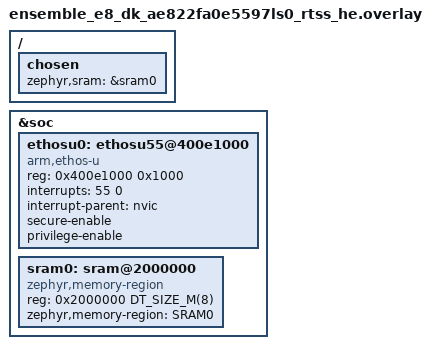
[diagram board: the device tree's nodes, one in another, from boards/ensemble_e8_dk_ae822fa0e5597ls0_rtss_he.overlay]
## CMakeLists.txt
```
# Copyright (c) Meta Platforms, Inc. and affiliates.
# All rights reserved.
# Copyright 2025-2026 Arm Limited and/or its affiliates.
#
# SPDX-License-Identifier: Apache-2.0

cmake_minimum_required(VERSION 3.24)

set(CMAKE_SKIP_INSTALL_RULES
    ON
    CACHE BOOL "" FORCE
)

set(ET_PTE_FILE_PATH
    ""
    CACHE FILEPATH "Path to the ExecuTorch .pte (or .bpte) model to embed"
)
set(ET_PTE_SECTION
    "network_model_sec"
    CACHE STRING "Section attribute used for the generated model data"
)

if(NOT ET_PTE_FILE_PATH)
  message(
    FATAL_ERROR
      "ET_PTE_FILE_PATH must point to the ExecuTorch .pte (or .bpte) model to embed."
  )
endif()

if(NOT IS_ABSOLUTE "${ET_PTE_FILE_PATH}")
  get_filename_component(
    ET_PTE_FILE_PATH "${ET_PTE_FILE_PATH}" ABSOLUTE BASE_DIR
    "${CMAKE_CURRENT_SOURCE_DIR}"
  )
endif()

if(NOT EXISTS "${ET_PTE_FILE_PATH}")
  message(
    FATAL_ERROR
      "Could not find ExecuTorch model at ET_PTE_FILE_PATH: ${ET_PTE_FILE_PATH}"
  )
endif()

set(ET_PTE_FILE_PATH
    "${ET_PTE_FILE_PATH}"
    CACHE FILEPATH "Path to the ExecuTorch .pte (or .bpte) model to embed"
          FORCE
)

find_package(
  Python3
  COMPONENTS Interpreter
  REQUIRED
)

execute_process(
  COMMAND
    ${Python3_EXECUTABLE}
    "${CMAKE_CURRENT_LIST_DIR}/../../../codegen/tools/gen_oplist.py"
    --model_file_path=${ET_PTE_FILE_PATH}
    --output_path=${CMAKE_CURRENT_BINARY_DIR}/temp.yaml
  RESULT_VARIABLE GEN_OPLIST_RESULT
  OUTPUT_VARIABLE CMD_RESULT
  ERROR_VARIABLE GEN_OPLIST_ERROR
)

if(NOT GEN_OPLIST_RESULT EQUAL 0)
  message(
    FATAL_ERROR
      "gen_oplist.py failed with exit code ${GEN_OPLIST_RESULT}: ${GEN_OPLIST_ERROR}"
  )
endif()

if(CMD_RESULT MATCHES "aten::" OR CMD_RESULT MATCHES "dim_order_ops::")
  set(FOUND_OPS_IN_FILE "true")
else()
  set(FOUND_OPS_IN_FILE "false")
endif()

if(${FOUND_OPS_IN_FILE})
  set(EXECUTORCH_SELECT_OPS_LIST "")
  set(EXECUTORCH_SELECT_OPS_MODEL
      "${ET_PTE_FILE_PATH}"
      CACHE STRING "Select operators from this ExecuTorch model" FORCE
  )
  set(_EXECUTORCH_GEN_ZEPHYR_PORTABLE_OPS ON)
  message(
    "gen_oplist:  EXECUTORCH_SELECT_OPS_MODEL=${ET_PTE_FILE_PATH} is used to auto generate ops from"
  )
else()
  set(EXECUTORCH_SELECT_OPS_LIST "")
  set(EXECUTORCH_SELECT_OPS_MODEL "")
  set(_EXECUTORCH_GEN_ZEPHYR_PORTABLE_OPS OFF)
  message(
    "gen_oplist: No aten:: or dim_order_ops:: operators were found in ${ET_PTE_FILE_PATH}; skipping portable operator selection. Other CPU operators may still run."
  )
endif()

find_package(Zephyr REQUIRED HINTS $ENV{ZEPHYR_BASE})

dt_nodelabel(model_ddr_path NODELABEL "model_ddr")
if(model_ddr_path)
  configure_file(
    model_section.ld.in ${CMAKE_CURRENT_BINARY_DIR}/model_section.ld @ONLY
  )
  zephyr_linker_sources(SECTIONS ${CMAKE_CURRENT_BINARY_DIR}/model_section.ld)
endif()

project(executorch_mv2_ethosu)

set(CMAKE_CXX_FLAGS
    "${CMAKE_CXX_FLAGS} -Wall -Wno-switch -Wno-float-conversion -ffunction-sections -fdata-sections"
)

if(NOT DEFINED EXECUTORCH_DIR)
  message(
    STATUS
      "ZEPHYR_EXECUTORCH_MODULE_DIR set to : ${ZEPHYR_EXECUTORCH_MODULE_DIR}"
  )
  if(DEFINED ZEPHYR_EXECUTORCH_MODULE_DIR)
    set(EXECUTORCH_DIR ${ZEPHYR_EXECUTORCH_MODULE_DIR})
    message(
      STATUS "Using Zephyr module discovery: EXECUTORCH_DIR=${EXECUTORCH_DIR}"
    )
  else()
    message(
      FATAL_ERROR
        "ExecuTorch module not found. Ensure it's properly configured in your Zephyr workspace."
    )
  endif()
else()
  message(STATUS "Using predefined EXECUTORCH_DIR=${EXECUTORCH_DIR}")
endif()

set(EXECUTORCH_ROOT ${EXECUTORCH_DIR})
include(${EXECUTORCH_DIR}/tools/cmake/Utils.cmake)

if(NOT TARGET portable_kernels)
  set(EXECUTORCH_PORTABLE_BUILD_KERNELS_ONLY ON)
  add_subdirectory(
    ${EXECUTORCH_DIR}/kernels/portable
    ${CMAKE_CURRENT_BINARY_DIR}/executorch/kernels/portable
  )
  unset(EXECUTORCH_PORTABLE_BUILD_KERNELS_ONLY)
endif()
set(EXECUTORCH_OPS_LIB "")
if(_EXECUTORCH_GEN_ZEPHYR_PORTABLE_OPS)
  include(${EXECUTORCH_DIR}/tools/cmake/Codegen.cmake)
  if(NOT DEFINED EXECUTORCH_ENABLE_DTYPE_SELECTIVE_BUILD)
    set(EXECUTORCH_ENABLE_DTYPE_SELECTIVE_BUILD "")
  endif()
  gen_selected_ops(
    LIB_NAME
    "cpu_portable_ops_lib"
    OPS_SCHEMA_YAML
    ""
    SELECT_OPS_LIST
    "${EXECUTORCH_SELECT_OPS_LIST}"
    INCLUDE_ALL_OPS
    ""
    OPS_FROM_MODEL
    "${EXECUTORCH_SELECT_OPS_MODEL}"
    DTYPE_SELECTIVE_BUILD
    "${EXECUTORCH_ENABLE_DTYPE_SELECTIVE_BUILD}"
  )
  generate_bindings_for_kernels(
    LIB_NAME "cpu_portable_ops_lib" FUNCTIONS_YAML
    ${EXECUTORCH_DIR}/kernels/portable/functions.yaml DTYPE_SELECTIVE_BUILD
    "${EXECUTORCH_ENABLE_DTYPE_SELECTIVE_BUILD}"
  )
  gen_operators_lib(
    LIB_NAME
    "cpu_portable_ops_lib"
    KERNEL_LIBS
    portable_kernels
    DEPS
    executorch
    DTYPE_SELECTIVE_BUILD
    "${EXECUTORCH_ENABLE_DTYPE_SELECTIVE_BUILD}"
  )
  set(EXECUTORCH_OPS_LIB "cpu_portable_ops_lib")
endif()

set(_local_flatcc_root ${CMAKE_BINARY_DIR}/flatcc_src)
if(NOT EXISTS ${_local_flatcc_root}/CMakeLists.txt)
  file(MAKE_DIRECTORY ${_local_flatcc_root})
  execute_process(
    COMMAND ${CMAKE_COMMAND} -E copy_directory
            ${EXECUTORCH_DIR}/third-party/flatcc ${_local_flatcc_root}
  )
endif()
set(EXECUTORCH_FLATCC_SOURCE_ROOT
    ${_local_flatcc_root}
    CACHE PATH "" FORCE
)
set(EXECUTORCH_FLATCC_INSTALL_ROOT
    ${_local_flatcc_root}
    CACHE PATH "" FORCE
)

set(app_sources src/main.cpp
                ${EXECUTORCH_DIR}/examples/arm/common/arm_memory_allocator.cpp
)
target_sources(app PRIVATE ${app_sources})

set(_model_pte_header ${CMAKE_CURRENT_BINARY_DIR}/model_pte.h)
add_custom_command(
  OUTPUT ${_model_pte_header}
  COMMAND
    ${Python3_EXECUTABLE} ${EXECUTORCH_DIR}/examples/arm/common/pte_to_header.py
    --pte ${ET_PTE_FILE_PATH} --outdir ${CMAKE_CURRENT_BINARY_DIR} --section
    ${ET_PTE_SECTION}
  DEPENDS ${ET_PTE_FILE_PATH}
          ${EXECUTORCH_DIR}/examples/arm/common/pte_to_header.py
  COMMENT "Converting ${ET_PTE_FILE_PATH} to model_pte.h"
)
add_custom_target(gen_model_header DEPENDS ${_model_pte_header})
add_dependencies(app gen_model_header)

if(DEFINED CONFIG_EXECUTORCH_METHOD_ALLOCATOR_POOL_SIZE)
  target_compile_definitions(
    app
    PRIVATE
      ET_ARM_METHOD_ALLOCATOR_POOL_SIZE=${CONFIG_EXECUTORCH_METHOD_ALLOCATOR_POOL_SIZE}
  )
endif()
if(DEFINED CONFIG_EXECUTORCH_TEMP_ALLOCATOR_POOL_SIZE)
  target_compile_definitions(
    app
    PRIVATE
      ET_ARM_BAREMETAL_SCRATCH_TEMP_ALLOCATOR_POOL_SIZE=${CONFIG_EXECUTORCH_TEMP_ALLOCATOR_POOL_SIZE}
  )
endif()
if(CONFIG_ET_ARM_MODEL_PTE_DMA_ACCESSIBLE)
  target_compile_definitions(app PRIVATE ET_ARM_MODEL_PTE_DMA_ACCESSIBLE)
endif()

target_link_libraries(app PRIVATE libexecutorch)
if(EXECUTORCH_OPS_LIB)
  target_link_libraries(app PRIVATE ${EXECUTORCH_OPS_LIB})
endif()
if(CONFIG_CPU_CORTEX_M)
  if(TARGET cortex_m_ops_lib)
    target_link_libraries(app PRIVATE cortex_m_ops_lib)
  endif()
  if(TARGET cortex_m_kernels)
    executorch_target_link_options_shared_lib(cortex_m_kernels)
    target_link_libraries(app PRIVATE cortex_m_kernels)
  endif()
endif()
if(TARGET quantized_kernels)
  executorch_target_link_options_shared_lib(quantized_kernels)
  target_link_libraries(app PRIVATE quantized_kernels)
endif()
if(TARGET portable_kernels)
  executorch_target_link_options_shared_lib(portable_kernels)
  target_link_libraries(app PRIVATE portable_kernels)
endif()
if(TARGET executorch_delegate_ethos_u)
  executorch_target_link_options_shared_lib(executorch_delegate_ethos_u)
  target_link_libraries(app PRIVATE executorch_delegate_ethos_u)
endif()
if(TARGET ethosu_core_driver)
  target_link_libraries(app PRIVATE ethosu_core_driver)
endif()

target_include_directories(app PRIVATE src ${CMAKE_CURRENT_BINARY_DIR})
get_target_property(OUT app LINK_LIBRARIES)
message(STATUS ${OUT})
```

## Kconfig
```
# Copyright (c) Meta Platforms, Inc. and affiliates.
# All rights reserved.
# Copyright 2025-2026 Arm Limited and/or its affiliates.
#
# SPDX-License-Identifier: Apache-2.0

source "Kconfig.zephyr"

menu "ExecuTorch MobileNetV2 sample configuration"

config ET_ARM_MODEL_PTE_DMA_ACCESSIBLE
	bool "Model PTE is in DMA-accessible memory"
	default n
	help
	  Skip copying the model PTE blob to a separate SRAM buffer at
	  runtime. Enable this when the embedded model blob already resides
	  in memory the Ethos-U NPU can DMA from (e.g. DDR on Corstone FVP,
	  MRAM on Alif). This is independent of where the linker places the
	  model section; DDR placement is controlled by the model_ddr DTS
	  node in the board overlay.

config EXECUTORCH_METHOD_ALLOCATOR_POOL_SIZE
	int "Method allocator pool size in bytes"
	default 1572864
	depends on EXECUTORCH
	help
	  Size of the method allocator pool in bytes. MobileNetV2 requires
	  more memory than simple models. Default is 1.5MB which is sufficient
	  for a fully NPU-delegated INT8 MobileNetV2 model.

config EXECUTORCH_TEMP_ALLOCATOR_POOL_SIZE
	int "Temporary allocator pool size in bytes"
	default 1572864
	depends on EXECUTORCH
	help
	  Size of the temporary allocator pool in bytes. Default is 1.5MB
	  which provides sufficient scratch space for MobileNetV2 inference
	  on Ethos-U NPU.

endmenu
```

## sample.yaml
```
sample:
  name: ExecuTorch MobileNetV2 Ethos-U
  description: MobileNetV2 image classification using ExecuTorch with Ethos-U NPU
common:
  tags:
    - executorch
    - ml
    - npu
    - ethos-u
    - mv2
    - image-classification
  depends_on:
    - executorch
    - arm_ethos_u
```

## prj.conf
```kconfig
# Copyright (c) Meta Platforms, Inc. and affiliates.
# All rights reserved.
# Copyright 2025-2026 Arm Limited and/or its affiliates.
#
# SPDX-License-Identifier: Apache-2.0

# Enable ExecuTorch
CONFIG_EXECUTORCH=y

# C++
CONFIG_CPP=y
CONFIG_STD_CPP17=y

# Config - increased for MobileNetV2 memory requirements
CONFIG_MAIN_STACK_SIZE=16384
CONFIG_HEAP_MEM_POOL_SIZE=65536

# Logging
CONFIG_REQUIRES_FLOAT_PRINTF=y

# Configuration for selective operator builds
CONFIG_EXECUTORCH_BUILD_PORTABLE_OPS=n

# Enable Helium (MVE) builds of CMSIS-NN by selecting the FPU and hard-float ABI.
CONFIG_FPU=y
CONFIG_FP_HARDABI=y

# Setup memory requirements for MobileNetV2.
# MV2 is a larger model than the default hello-executorch add model.
CONFIG_EXECUTORCH_METHOD_ALLOCATOR_POOL_SIZE=1572864
CONFIG_EXECUTORCH_TEMP_ALLOCATOR_POOL_SIZE=1572864
```

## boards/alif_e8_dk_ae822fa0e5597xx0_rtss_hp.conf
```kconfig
# Copyright (c) Meta Platforms, Inc. and affiliates.
#
# Copyright 2026 Arm Limited and/or its affiliates.
#
# SPDX-License-Identifier: Apache-2.0
#
# Alif Ensemble E8 DevKit (HP core): Ethos-U55 with 256 MACs.
# MRAM is DMA-accessible by the NPU so no SRAM copy is needed.
CONFIG_ETHOS_U=y
CONFIG_ET_ARM_MODEL_PTE_DMA_ACCESSIBLE=y
```

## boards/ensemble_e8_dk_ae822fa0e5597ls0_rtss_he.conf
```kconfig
# Copyright (c) Meta Platforms, Inc. and affiliates.
#
# Copyright 2026 Arm Limited and/or its affiliates.
#
# SPDX-License-Identifier: Apache-2.0

# Keep the linked image address in sync with the Alif ATOC mramAddress used by
# this sample's generated zephyr.json.
CONFIG_FLASH_LOAD_OFFSET=0x8000

# Enable the Zephyr Ethos-U driver so the ExecuTorch Arm backend is built and
# the EthosUBackend delegate is registered at runtime.
CONFIG_ETHOS_U=y
CONFIG_ETHOS_U55_128=y

# Alif MRAM is DMA-accessible by the NPU, so avoid duplicating the model into
# SRAM at startup.
CONFIG_ET_ARM_MODEL_PTE_DMA_ACCESSIBLE=y
```

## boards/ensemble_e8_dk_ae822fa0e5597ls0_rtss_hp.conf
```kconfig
# Copyright (c) Meta Platforms, Inc. and affiliates.
#
# Copyright 2026 Arm Limited and/or its affiliates.
#
# SPDX-License-Identifier: Apache-2.0

# Keep the linked image address in sync with the Alif ATOC mramAddress used by
# this sample's generated zephyr.json.
CONFIG_FLASH_LOAD_OFFSET=0x8000

# Enable the Zephyr Ethos-U driver so the ExecuTorch Arm backend is built and
# the EthosUBackend delegate is registered at runtime.
CONFIG_ETHOS_U=y
CONFIG_ETHOS_U55_256=y

# Alif MRAM is DMA-accessible by the NPU, so avoid duplicating the model into
# SRAM at startup.
CONFIG_ET_ARM_MODEL_PTE_DMA_ACCESSIBLE=y
```

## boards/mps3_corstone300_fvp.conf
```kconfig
# Copyright (c) Meta Platforms, Inc. and affiliates.
#
# Copyright 2026 Arm Limited and/or its affiliates.
#
# SPDX-License-Identifier: Apache-2.0
#
# Enable the Zephyr Ethos-U driver so executorch_delegate_ethos_u can reserve
# and use the hardware instance exposed by the board DTS.
CONFIG_ETHOS_U=y

# Model PTE is placed in DDR via linker snippet; the Ethos-U can DMA from
# DDR on the FVP so no SRAM copy is needed.
CONFIG_ET_ARM_MODEL_PTE_DMA_ACCESSIBLE=y

# Corstone-300 has 2 MiB ISRAM.  With the model in DDR the method pool
# needs ~1.4 MiB (752 KiB planned buffer + 602 KiB input tensor).
# The remaining ISRAM is not enough for the Ethos-U scratch (~1.5 MiB),
# so MV2 inference will fail at runtime on this board; Corstone-320 is
# the supported target for MV2.  These sizes keep the link step green.
CONFIG_EXECUTORCH_METHOD_ALLOCATOR_POOL_SIZE=786432
CONFIG_EXECUTORCH_TEMP_ALLOCATOR_POOL_SIZE=786432
```

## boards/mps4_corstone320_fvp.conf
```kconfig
# Copyright (c) Meta Platforms, Inc. and affiliates.
#
# Copyright 2026 Arm Limited and/or its affiliates.
#
# SPDX-License-Identifier: Apache-2.0
#
# Enable the Zephyr Ethos-U driver so executorch_delegate_ethos_u can reserve
# and use the hardware instance exposed by the board DTS.
CONFIG_ETHOS_U=y

# Model PTE is placed in DDR via linker snippet; the Ethos-U can DMA from
# DDR on the FVP so no SRAM copy is needed.
CONFIG_ET_ARM_MODEL_PTE_DMA_ACCESSIBLE=y

# The overlay reserves 3.5 MiB of ISRAM for writable data, including these pools.
CONFIG_EXECUTORCH_METHOD_ALLOCATOR_POOL_SIZE=1572864
CONFIG_EXECUTORCH_TEMP_ALLOCATOR_POOL_SIZE=1572864
```

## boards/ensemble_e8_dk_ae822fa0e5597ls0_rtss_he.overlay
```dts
/* Copyright (c) Meta Platforms, Inc. and affiliates.
 *
 * Copyright 2026 Arm Limited and/or its affiliates.
 *
 * SPDX-License-Identifier: Apache-2.0
 */

/* The default board DTS routes Zephyr RAM to 256 KiB DTCM on RTSS-HE.
 * MobileNetV2 needs much more space, so expose the contiguous SRAM0 and SRAM1
 * banks as one 8 MiB Zephyr RAM region for this sample.
 */

/delete-node/ &sram0;
/delete-node/ &sram1;

&soc {
	ethosu0: ethosu55@400e1000 {
		compatible = "arm,ethos-u";
		reg = <0x400e1000 0x1000>;
		interrupts = <55 0>;
		interrupt-parent = <&nvic>;
		secure-enable;
		privilege-enable;
		status = "okay";
	};

	sram0: sram@2000000 {
		compatible = "zephyr,memory-region", "mmio-sram";
		reg = <0x2000000 DT_SIZE_M(8)>;
		zephyr,memory-region = "SRAM0";
	};
};

/ {
	chosen {
		zephyr,sram = &sram0;
	};
};
```

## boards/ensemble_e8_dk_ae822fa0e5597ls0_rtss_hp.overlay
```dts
/* Copyright (c) Meta Platforms, Inc. and affiliates.
 *
 * Copyright 2026 Arm Limited and/or its affiliates.
 *
 * SPDX-License-Identifier: Apache-2.0
 */

/* The default board DTS routes Zephyr RAM to 1 MiB DTCM. MobileNetV2 allocator
 * pools exceed that space, so expose the contiguous SRAM0 and SRAM1 banks as
 * one 8 MiB Zephyr RAM region for this sample.
 */

/delete-node/ &sram0;
/delete-node/ &sram1;

&soc {
	ethosu0: ethosu55@400e1000 {
		compatible = "arm,ethos-u";
		reg = <0x400e1000 0x1000>;
		interrupts = <55 0>;
		interrupt-parent = <&nvic>;
		secure-enable;
		privilege-enable;
		status = "okay";
	};

	sram0: sram@2000000 {
		compatible = "zephyr,memory-region", "mmio-sram";
		reg = <0x2000000 DT_SIZE_M(8)>;
		zephyr,memory-region = "SRAM0";
	};
};

/ {
	chosen {
		zephyr,sram = &sram0;
	};
};
```

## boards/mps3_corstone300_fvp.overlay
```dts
/* Copyright (c) Meta Platforms, Inc. and affiliates.
 *
 * Copyright 2026 Arm Limited and/or its affiliates.
 *
 * SPDX-License-Identifier: Apache-2.0
 */

/* Ensure ExecuTorch scratch buffers live in shared SRAM that the Ethos-U
 * DMA can access. The default board DTS routes Zephyr's general-purpose
 * SRAM to DTCM, which the NPU cannot reach. Override the choice so that
 * .data/.bss land in ISRAM (0x3100_0000) instead.
 *
 * The model PTE blob is placed in DDR (0x7000_0000) via a linker snippet
 * to avoid overflowing the 2 MiB ISRAM and 512 KiB ITCM regions.
 * The Ethos-U can DMA from DDR on the Corstone-300 FVP.
 */
/ {
	chosen {
		zephyr,sram = &isram;
	};

	model_ddr: memory@70000000 {
		compatible = "zephyr,memory-region", "mmio-sram";
		reg = <0x70000000 DT_SIZE_M(16)>;
		zephyr,memory-region = "MODEL_DDR";
	};
};
```

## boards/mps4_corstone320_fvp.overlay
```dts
/* Copyright (c) Meta Platforms, Inc. and affiliates.
 *
 * Copyright 2026 Arm Limited and/or its affiliates.
 *
 * SPDX-License-Identifier: Apache-2.0
 */

/* The board uses ISRAM for XIP code. Reserve its first 512 KiB for code
 * and the remaining 3.5 MiB for writable data and allocator pools. Using
 * the same region for zephyr,flash and zephyr,sram overlaps code and data.
 *
 * The model PTE blob is placed in DDR (0x7000_0000) via a linker snippet.
 * The Ethos-U can DMA from DDR on the Corstone-320 FVP.
 */
&isram {
	reg = <0x31000000 DT_SIZE_K(512)>;
};

/ {
	chosen {
		zephyr,sram = &executorch_sram;
	};

	executorch_sram: memory@31080000 {
		compatible = "zephyr,memory-region", "mmio-sram";
		reg = <0x31080000 DT_SIZE_K(3584)>;
		zephyr,memory-region = "EXECUTORCH_SRAM";
	};

	model_ddr: memory@70000000 {
		compatible = "zephyr,memory-region", "mmio-sram";
		reg = <0x70000000 DT_SIZE_M(16)>;
		zephyr,memory-region = "MODEL_DDR";
	};
};
```

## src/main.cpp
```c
/* Copyright (c) Meta Platforms, Inc. and affiliates.
 * All rights reserved.
 * Copyright 2025-2026 Arm Limited and/or its affiliates.
 *
 * This source code is licensed under the BSD-style license found in the
 * LICENSE file in the root directory of this source tree.
 *
 * MobileNetV2 Image Classification using ExecuTorch with Ethos-U NPU
 */

#include <executorch/examples/arm/common/arm_memory_allocator.h>
#include <executorch/extension/data_loader/buffer_data_loader.h>
#include <executorch/runtime/executor/program.h>
#include <executorch/runtime/platform/log.h>
#include <executorch/runtime/platform/platform.h>
#include <executorch/runtime/platform/runtime.h>
#include <stdio.h>
#include <zephyr/kernel.h>
#include <zephyr/sys/printk.h>
#include <cinttypes>
#include <cstring>
#include <vector>

#include "model_pte.h"
#include "mv2_input.h"

// Runtime view of the model blob used by Ethos-U DMA for command stream and
// weights. By default we keep a writable SRAM copy because some targets (e.g.
// Corstone FVP) place model_pte[] in flash which is not DMA-accessible.
// Boards that can DMA directly from the embedded model blob (e.g. Alif
// Ensemble with MRAM) should define ET_ARM_MODEL_PTE_DMA_ACCESSIBLE at build
// time to avoid the SRAM duplicate.
#if defined(ET_ARM_MODEL_PTE_DMA_ACCESSIBLE)
static const unsigned char* model_pte_ptr = model_pte;
#else
alignas(16) static unsigned char model_pte_runtime[sizeof(model_pte)];
static bool model_pte_runtime_initialized = false;
#endif

using executorch::aten::ScalarType;
using executorch::aten::Tensor;
using executorch::aten::TensorImpl;
using executorch::extension::BufferDataLoader;
using executorch::runtime::Error;
using executorch::runtime::EValue;
using executorch::runtime::HierarchicalAllocator;
using executorch::runtime::MemoryAllocator;
using executorch::runtime::MemoryManager;
using executorch::runtime::Method;
using executorch::runtime::MethodMeta;
using executorch::runtime::Program;
using executorch::runtime::Result;
using executorch::runtime::Span;
using executorch::runtime::Tag;
using executorch::runtime::TensorInfo;

#if !defined(ET_ARM_METHOD_ALLOCATOR_POOL_SIZE)
#define ET_ARM_METHOD_ALLOCATOR_POOL_SIZE (1572864)
#endif
const size_t method_allocation_pool_size = ET_ARM_METHOD_ALLOCATOR_POOL_SIZE;
unsigned char __attribute__((
    aligned(16))) method_allocation_pool[method_allocation_pool_size];

#if !defined(ET_ARM_BAREMETAL_SCRATCH_TEMP_ALLOCATOR_POOL_SIZE)
#define ET_ARM_BAREMETAL_SCRATCH_TEMP_ALLOCATOR_POOL_SIZE (1572864)
#endif

#if !defined(ET_ARM_BAREMETAL_FAST_SCRATCH_TEMP_ALLOCATOR_POOL_SIZE)
#define ET_ARM_BAREMETAL_FAST_SCRATCH_TEMP_ALLOCATOR_POOL_SIZE 0x600
#endif

const size_t temp_allocation_pool_size =
    ET_ARM_BAREMETAL_SCRATCH_TEMP_ALLOCATOR_POOL_SIZE;
unsigned char __attribute__((
    section(".bss.tensor_arena"),
    aligned(16))) temp_allocation_pool[temp_allocation_pool_size];

#if defined(ET_ARM_BAREMETAL_FAST_SCRATCH_TEMP_ALLOCATOR_POOL_SIZE)
extern "C" {
size_t ethosu_fast_scratch_size =
    ET_ARM_BAREMETAL_FAST_SCRATCH_TEMP_ALLOCATOR_POOL_SIZE;
unsigned char __attribute__((section(".bss.ethosu_scratch"), aligned(16)))
dedicated_sram[ET_ARM_BAREMETAL_FAST_SCRATCH_TEMP_ALLOCATOR_POOL_SIZE];
unsigned char* ethosu_fast_scratch = dedicated_sram;
}
#endif

#define MV2_NUM_OUTPUT_CLASSES 1000
#define MV2_TOP_K 5

namespace {

// Preprocessing constants for torchvision's ImageNet-trained MobileNetV2.
constexpr size_t kNumChannels = 3;
constexpr float kImageNetMean[kNumChannels] = {0.485f, 0.456f, 0.406f};
constexpr float kImageNetStd[kNumChannels] = {0.229f, 0.224f, 0.225f};

Error prepare_input_tensors(
    Method& method,
    MemoryAllocator& allocator,
    const uint8_t* input_data,
    size_t input_size) {
  MethodMeta method_meta = method.method_meta();
  size_t num_inputs = method_meta.num_inputs();
  size_t tensor_inputs_seen = 0;

  for (size_t i = 0; i < num_inputs; i++) {
    auto tag = method_meta.input_tag(i);
    if (!tag.ok()) {
      return tag.error();
    }

    if (tag.get() != Tag::Tensor) {
      ET_LOG(Debug, "Skipping non-tensor input %zu", i);
      continue;
    }
    if (tensor_inputs_seen > 0) {
      ET_LOG(
          Error,
          "Model has multiple tensor inputs; this sample supports only one");
      return Error::InvalidArgument;
    }
    tensor_inputs_seen++;

    Result<TensorInfo> tensor_meta = method_meta.input_tensor_meta(i);
    if (!tensor_meta.ok()) {
      return tensor_meta.error();
    }

    void* data_ptr = allocator.allocate(tensor_meta->nbytes());
    if (data_ptr == nullptr) {
      ET_LOG(Error, "Could not allocate memory for input buffer");
      return Error::MemoryAllocationFailed;
    }

    ScalarType scalar_type = tensor_meta->scalar_type();
    size_t num_elements = 1;
    auto sizes = tensor_meta->sizes();
    for (size_t k = 0; k < sizes.size(); k++) {
      num_elements *= sizes[k];
    }

    ET_LOG(
        Info,
        "Input tensor: scalar_type=%s, numel=%lu, nbytes=%lu",
        executorch::runtime::toString(scalar_type),
        static_cast<unsigned long>(num_elements),
        static_cast<unsigned long>(tensor_meta->nbytes()));

    if (scalar_type == ScalarType::Float && input_size == num_elements) {
      ET_LOG(
          Info,
          "Converting uint8 input (%lu elements) to float32",
          static_cast<unsigned long>(input_size));
      // torchvision MobileNetV2 is trained with ImageNet normalisation, so the
      // uint8 image has to be scaled to [0,1] and then standardised per
      // channel. The tensor is NCHW, so each channel is a contiguous plane.
      float* float_data = static_cast<float*>(data_ptr);
      const size_t plane = input_size / kNumChannels;
      for (size_t c = 0; c < kNumChannels; c++) {
        const float mean = kImageNetMean[c];
        const float stddev = kImageNetStd[c];
        for (size_t j = 0; j < plane; j++) {
          const size_t idx = c * plane + j;
          float_data[idx] =
              ((static_cast<float>(input_data[idx]) / 255.0f) - mean) / stddev;
        }
      }
    } else if (input_size == tensor_meta->nbytes()) {
      ET_LOG(
          Info,
          "Copying input data to tensor (%lu bytes)",
          static_cast<unsigned long>(input_size));
      std::memcpy(data_ptr, input_data, input_size);
    } else {
      ET_LOG(
          Error,
          "Input size (%lu) and tensor size (%lu elements, %lu bytes) mismatch!",
          static_cast<unsigned long>(input_size),
          static_cast<unsigned long>(num_elements),
          static_cast<unsigned long>(tensor_meta->nbytes()));
      return Error::InvalidArgument;
    }

    TensorImpl impl = TensorImpl(
        tensor_meta.get().scalar_type(),
        tensor_meta.get().sizes().size(),
        const_cast<TensorImpl::SizesType*>(tensor_meta.get().sizes().data()),
        data_ptr,
        const_cast<TensorImpl::DimOrderType*>(
            tensor_meta.get().dim_order().data()));
    Tensor t(&impl);

    Error err = method.set_input(t, i);
    if (err != Error::Ok) {
      ET_LOG(
          Error, "Failed to prepare input %zu: 0x%" PRIx32, i, (uint32_t)err);
      return err;
    }
  }
  return Error::Ok;
}

void print_top_k(const std::vector<EValue>& outputs) {
  if (outputs.empty() || !outputs[0].isTensor()) {
    ET_LOG(Error, "Output is not a tensor");
    return;
  }

  Tensor output_tensor = outputs[0].toTensor();
  ScalarType scalar_type = output_tensor.scalar_type();
  size_t num_classes = output_tensor.numel();

  ET_LOG(
      Info,
      "Output tensor: scalar_type=%s, numel=%lu",
      executorch::runtime::toString(scalar_type),
      static_cast<unsigned long>(num_classes));

  int top_indices[MV2_TOP_K] = {0};
  float top_values[MV2_TOP_K];

  for (int j = 0; j < MV2_TOP_K; j++) {
    top_values[j] = -1e9f;
  }

  for (size_t i = 0; i < num_classes; i++) {
    float val;
    switch (scalar_type) {
      case ScalarType::Float:
        val = output_tensor.const_data_ptr<float>()[i];
        break;
      case ScalarType::Int:
        val = static_cast<float>(output_tensor.const_data_ptr<int>()[i]);
        break;
      case ScalarType::Char:
        val = static_cast<float>(output_tensor.const_data_ptr<int8_t>()[i]);
        break;
      case ScalarType::Byte:
        val = static_cast<float>(output_tensor.const_data_ptr<uint8_t>()[i]);
        break;
      default:
        ET_LOG(
            Error,
            "Unsupported output scalar type: %s",
            executorch::runtime::toString(scalar_type));
        return;
    }

    for (int j = 0; j < MV2_TOP_K; j++) {
      if (val > top_values[j]) {
        for (int m = MV2_TOP_K - 1; m > j; m--) {
          top_values[m] = top_values[m - 1];
          top_indices[m] = top_indices[m - 1];
        }
        top_values[j] = val;
        top_indices[j] = static_cast<int>(i);
        break;
      }
    }
  }

  ET_LOG(Info, "\nTop-%d predictions:", MV2_TOP_K);
  for (int j = 0; j < MV2_TOP_K; j++) {
    ET_LOG(
        Info,
        "  [%d] class %d: %.4f",
        j + 1,
        top_indices[j],
        static_cast<double>(top_values[j]));
  }

#if defined(MV2_HOST_TOP1) && defined(MV2_HOST_LABEL)
  // gen_input.py records what float32 torchvision predicts for this image, so
  // the class ID can be interpreted without an ImageNet label table on target.
  ET_LOG(
      Info,
      "\nhost float32 reference: class %d (%s) -> device top-1 %s",
      MV2_HOST_TOP1,
      MV2_HOST_LABEL,
      (top_indices[0] == MV2_HOST_TOP1) ? "MATCHES" : "DIFFERS");
#endif
}

} // namespace

int main(void) {
  printk("\n========================================\n");
  printk("ExecuTorch MobileNetV2 Classification Demo\n");
  printk("========================================\n\n");

  executorch::runtime::runtime_init();

  size_t pte_size = sizeof(model_pte);
  ET_LOG(
      Info,
      "Model PTE at %p, Size: %lu bytes",
      model_pte,
      static_cast<unsigned long>(pte_size));

#if defined(ET_ARM_MODEL_PTE_DMA_ACCESSIBLE)
  const void* program_data = model_pte_ptr;
#else
  if (!model_pte_runtime_initialized) {
    std::memcpy(model_pte_runtime, model_pte, sizeof(model_pte));
    model_pte_runtime_initialized = true;
  }
  const void* program_data = model_pte_runtime;
#endif
  size_t program_data_len = pte_size;

  auto loader = BufferDataLoader(program_data, program_data_len);
  ET_LOG(
      Info,
      "Model data loaded. Size: %lu bytes.",
      static_cast<unsigned long>(program_data_len));

  Result<Program> program = Program::load(&loader);
  if (!program.ok()) {
    ET_LOG(
        Error,
        "Program loading failed @ 0x%p: 0x%" PRIx32,
        program_data,
        static_cast<uint32_t>(program.error()));
    return 1;
  }

  ET_LOG(
      Info,
      "Model loaded, has %lu methods",
      static_cast<unsigned long>(program->num_methods()));

  const char* method_name = nullptr;
  {
    const auto method_name_result = program->get_method_name(0);
    ET_CHECK_MSG(method_name_result.ok(), "Program has no methods");
    method_name = *method_name_result;
  }
  ET_LOG(Info, "Running method: %s", method_name);

  Result<MethodMeta> method_meta = program->method_meta(method_name);
  if (!method_meta.ok()) {
    ET_LOG(
        Error,
        "Failed to get method_meta for %s: 0x%x",
        method_name,
        (unsigned int)method_meta.error());
    return 1;
  }

  ET_LOG(
      Info,
      "Method allocator pool size: %lu bytes.",
      static_cast<unsigned long>(method_allocation_pool_size));

  ArmMemoryAllocator method_allocator(
      method_allocation_pool_size, method_allocation_pool);

  std::vector<uint8_t*> planned_buffers;
  std::vector<Span<uint8_t>> planned_spans;
  size_t num_memory_planned_buffers = method_meta->num_memory_planned_buffers();

  for (size_t id = 0; id < num_memory_planned_buffers; ++id) {
    Result<int64_t> buffer_size_result =
        method_meta->memory_planned_buffer_size(id);
    if (!buffer_size_result.ok()) {
      ET_LOG(
          Error,
          "Failed to get planned buffer size for buffer %lu: 0x%x",
          static_cast<unsigned long>(id),
          (unsigned int)buffer_size_result.error());
      return 1;
    }
    size_t buffer_size = static_cast<size_t>(buffer_size_result.get());
    ET_LOG(
        Info,
        "Setting up planned buffer %lu, size %lu.",
        static_cast<unsigned long>(id),
        static_cast<unsigned long>(buffer_size));

    uint8_t* buffer =
        reinterpret_cast<uint8_t*>(method_allocator.allocate(buffer_size));
    ET_CHECK_MSG(
        buffer != nullptr,
        "Could not allocate planned buffer size %lu",
        static_cast<unsigned long>(buffer_size));
    planned_buffers.push_back(buffer);
    planned_spans.push_back({planned_buffers.back(), buffer_size});
  }

  HierarchicalAllocator planned_memory(
      {planned_spans.data(), planned_spans.size()});

  ArmMemoryAllocator temp_allocator(
      temp_allocation_pool_size, temp_allocation_pool);

  MemoryManager memory_manager(
      &method_allocator, &planned_memory, &temp_allocator);

  ET_LOG(Info, "Loading method...");
  executorch::runtime::EventTracer* event_tracer_ptr = nullptr;

  Result<Method> method =
      program->load_method(method_name, &memory_manager, event_tracer_ptr);

  if (!method.ok()) {
    ET_LOG(
        Error,
        "Loading of method %s failed with status 0x%" PRIx32,
        method_name,
        static_cast<uint32_t>(method.error()));
    return 1;
  }
  ET_LOG(Info, "Method '%s' loaded successfully", method_name);

  ET_LOG(
      Info,
      "Preparing input: static RGB image (%lu bytes)",
      static_cast<unsigned long>(sizeof(mv2_input_data)));

  {
    Error input_err = ::prepare_input_tensors(
        *method, method_allocator, mv2_input_data, sizeof(mv2_input_data));

    if (input_err != Error::Ok) {
      ET_LOG(
          Error,
          "Preparing input failed: 0x%" PRIx32,
          static_cast<uint32_t>(input_err));
      return 1;
    }
  }

  ET_LOG(Info, "\n--- Starting inference ---");
  uint32_t start_time = k_uptime_get_32();

  Error status = method->execute();

  uint32_t end_time = k_uptime_get_32();
  uint32_t inference_time = end_time - start_time;

  if (status != Error::Ok) {
    ET_LOG(
        Error, "Execution failed: 0x%" PRIx32, static_cast<uint32_t>(status));
    return 1;
  }
  ET_LOG(Info, "Inference completed in %u ms", inference_time);

  std::vector<EValue> outputs(method->outputs_size());
  status = method->get_outputs(outputs.data(), outputs.size());
  if (status != Error::Ok) {
    ET_LOG(
        Error, "get_outputs failed: 0x%" PRIx32, static_cast<uint32_t>(status));
    return 1;
  }

  ET_LOG(Info, "\n--- Classification Results ---");
  print_top_k(outputs);

  ET_LOG(Info, "\n========================================");
  ET_LOG(Info, "MobileNetV2 Demo Complete");
  ET_LOG(Info, "Model size: %lu bytes", static_cast<unsigned long>(pte_size));
  ET_LOG(
      Info,
      "Input: [1, 3, 224, 224] NCHW RGB tensor (%lu bytes)",
      static_cast<unsigned long>(sizeof(mv2_input_data)));
  size_t num_output_classes = (!outputs.empty() && outputs[0].isTensor())
      ? outputs[0].toTensor().numel()
      : MV2_NUM_OUTPUT_CLASSES;
  ET_LOG(
      Info,
      "Output: %lu classes (top-%d shown)",
      static_cast<unsigned long>(num_output_classes),
      MV2_TOP_K);
  ET_LOG(Info, "Inference time: %u ms", inference_time);
  ET_LOG(Info, "========================================\n");

  return 0;
}
```
